# IWRL6432 register map
File version: 1.0
CPU: CM4 1.0, other endian, MPU, FPU, 3 interrupt priority bits
Registers are 32-bit, read-write, reset 0x0 unless marked. A register's access mark holds for its fields unless they carry their own. Offsets are from the block's base; [hi:lo] are bit positions.

## APP_PWM (part 2 of 2)
Base 0x57F7FC00
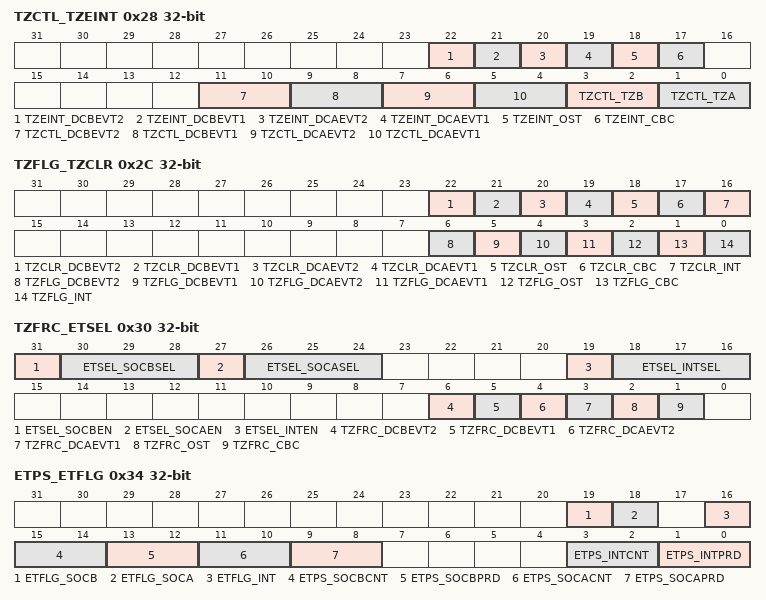
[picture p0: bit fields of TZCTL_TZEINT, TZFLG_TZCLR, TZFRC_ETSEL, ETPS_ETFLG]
0x28 TZCTL_TZEINT — Trip-Zone Control Register/ Trip-Zone Enable Interrupt Register
  [22] TZEINT_DCBEVT2 — [22:22] Digital Comparator Output B Event 2 Interrupt Enable 0 Disabled 1 Enabled
  [21] TZEINT_DCBEVT1 — [21:21] Digital Comparator Output B Event 1 Interrupt Enable 0 Disabled 1 Enabled
  [20] TZEINT_DCAEVT2 — [20:20] Digital Comparator Output A Event 2 Interrupt Enable 0 Disabled 1 Enabled
  [19] TZEINT_DCAEVT1 — [19:19] Digital Comparator Output A Event 1 Interrupt Enable 0 Disabled 1 Enabled
  [18] TZEINT_OST — [18:18] Trip-zone One-Shot Interrupt Enable 0 Disable one-shot interrupt generation 1 Enable Interrupt generation; a one-shot trip event will cause a EPWMx_TZINT VIM interrupt
  [17] TZEINT_CBC — [17:17] Trip-zone Cycle-by-Cycle Interrupt Enable 0 Disable cycle-by-cycle interrupt generation. 1 Enable interrupt generation; a cycle-by-cycle trip event will cause an EPWMx_TZINT VIM interrupt
  [11:10] TZCTL_DCBEVT2 — [11:10] Digital Compare Output B Event 2 Action On EPWMxB: 0 High-impedance (EPWMxB = High-impedance state) 1h Force EPWMxB to a high state. 2h Force EPWMxB to a low state. 3h Do Nothing, trip action is disabled
  [9:8] TZCTL_DCBEVT1 — [9:8] Digital Compare Output B Event 1 Action On EPWMxB: 0 High-impedance (EPWMxB = High-impedance state) 1h Force EPWMxB to a high state. 2h Force EPWMxB to a low state. 3h Do Nothing, trip action is disabled
  [7:6] TZCTL_DCAEVT2 — [7:6] Digital Compare Output A Event 2 Action On EPWMxA: 0 High-impedance (EPWMxA = High-impedance state) 1h Force EPWMxA to a high state. 2h Force EPWMxA to a low state. 3h Do Nothing, trip action is disabled
  [5:4] TZCTL_DCAEVT1 — [5:4] Digital Compare Output A Event 1 Action On EPWMxA: 0 High-impedance (EPWMxA = High-impedance state) 1h Force EPWMxA to a high state. 2h Force EPWMxA to a low state. 3h Do Nothing, trip action is disabled
  [3:2] TZCTL_TZB — [3:2] When a trip event occurs the following action is taken on output EPWMxB. Which trip-zone pins can cause an event is defined in the TZSEL register. 0 High-impedance (EPWMxB = High-impedance state) 1h Force EPWMxB to a high state 2h Force EPWMxB to a low state 3h Do nothing, no action is taken on EPWMxB.
  [1:0] TZCTL_TZA — [1:0] When a trip event occurs the following action is taken on output EPWMxA. Which trip-zone pins can cause an event is defined in the TZSEL register. 0 High-impedance (EPWMxA = High-impedance state) 1h Force EPWMxA to a high state 2h Force EPWMxA to a low state 3h Do nothing, no action is taken on EPWMxA
0x2C TZFLG_TZCLR — Trip-Zone Flag Register/ Trip-Zone Clear Register
  [22] TZCLR_DCBEVT2 — [22:22] Clear Flag for Digital Compare Output B Event 2 0 Writing 0 has no effect. This bit always reads back 0. 1 Writing 1 clears the DCBEVT2 event trip condition.
  [21] TZCLR_DCBEVT1 — [21:21] Clear Flag for Digital Compare Output B Event 1 0 Writing 0 has no effect. This bit always reads back 0. 1 Writing 1 clears the DCBEVT1 event trip condition
  [20] TZCLR_DCAEVT2 — [20:20] Clear Flag for Digital Compare Output A Event 2 0 Writing 0 has no effect. This bit always reads back 0. 1 Writing 1 clears the DCAEVT2 event trip condition
  [19] TZCLR_DCAEVT1 — [19:19] Clear Flag for Digital Compare Output A Event 1 0 Writing 0 has no effect. This bit always reads back 0. 1 Writing 1 clears the DCAEVT1 event trip condition.
  [18] TZCLR_OST — [18:18] Clear Flag for One-Shot Trip (OST) Latch 0 Has no effect. Always reads back a 0. 1 Clears this Trip (set) condition.
  [17] TZCLR_CBC — [17:17] Clear Flag for Cycle-By-Cycle (CBC) Trip Latch 0 Has no effect. Always reads back a 0. 1 Clears this Trip (set) condition.
  [16] TZCLR_INT — [16:16] Global Interrupt Clear Flag 0 Has no effect. Always reads back a 0. 1 Clears the trip-interrupt flag for this ePWM module (TZFLG[INT]). NOTE: No further EPWMx_TZINT VIM interrupts will be generated until the flag is cleared. If the TZFLG[INT] bit is cleared and any of the other flag bits are set, then another interrupt pulse will be generated. Clearing all flag bits will prevent further interrupts.
  [6] TZFLG_DCBEVT2 — [6:6] Latched Status Flag for Digital Compare Output B Event 2 0 Indicates no trip event has occurred on DCBEVT2 1 Indicates a trip event has occurred for the event defined for DCBEVT2
  [5] TZFLG_DCBEVT1 — [5:5] Latched Status Flag for Digital Compare Output B Event 1 0 Indicates no trip event has occurred on DCBEVT1 1 Indicates a trip event has occurred for the event defined for DCBEVT1
  [4] TZFLG_DCAEVT2 — [4:4] Latched Status Flag for Digital Compare Output A Event 2 0 Indicates no trip event has occurred on DCAEVT2 1 Indicates a trip event has occurred for the event defined for DCAEVT2
  [3] TZFLG_DCAEVT1 — [3:3] Latched Status Flag for Digital Compare Output A Event 1 0 Indicates no trip event has occurred on DCAEVT1 1 Indicates a trip event has occurred for the event defined for DCAEVT1
  [2] TZFLG_OST — [2:2] Latched Status Flag for A One-Shot Trip Event 0 No one-shot trip event has occurred. 1 Indicates a trip event has occurred on a pin selected as a one-shot trip source. This bit is cleared by writing the appropriate value to the TZCLR register
  [1] TZFLG_CBC — [1:1] Latched Status Flag for Cycle-By-Cycle Trip Event 0 No cycle-by-cycle trip event has occurred. 1 Indicates a trip event has occurred on a signal selected as a cycle-by-cycle trip source. The TZFLG[CBC] bit will remain set until it is manually cleared by the user. If the cycle-by-cycle trip event is still present when the CBC bit is cleared, then CBC will be immediately set again. The specified condition on the signal is automatically cleared when the ePWM time-base counter reaches zero (TBCTR = 0x0000) if the trip condition is no longer present. The condition on the signal is only cleared when the TBCTR = 0x0000 no matter where in the cycle the CBC flag is cleared. This bit is cleared by writing the appropriate value to the TZCLR register
  [0] TZFLG_INT — [0:0] Latched Trip Interrupt Status Flag 0 Indicates no interrupt has been generated. 1 Indicates an EPWMx_TZINT VIM interrupt was generated because of a trip condition. No further EPWMx_TZINT VIM interrupts will be generated until this flag is cleared. If the interrupt flag is cleared when either CBC or OST is set, then another interrupt pulse will be generated. Clearing all flag bits will prevent further interrupts. This bit is cleared by writing the appropriate value to the TZCLR register
0x30 TZFRC_ETSEL — Trip-Zone Force Register / Event-Trigger Selection Register
  [31] ETSEL_SOCBEN — [31:31] Enable the ADC Start of Conversion B (EPWMxSOCB) Pulse 0 Disable EPWMxSOCB. 1 Enable EPWMxSOCB pulse
  [30:28] ETSEL_SOCBSEL — [30:28] EPWMxSOCB Selection Options These bits determine when a EPWMxSOCB pulse will be generated. 0 Enable DCBEVT1.soc event 1h Enable event time-base counter equal to zero. (TBCTR = 0x0000) 2h Enable event time-base counter equal to period (TBCTR = TBPRD) 3h Enable event time-base counter equal to zero or period (TBCTR = 0x0000 or TBCTR = TBPRD). This mode is useful in up-down count mode. 4h Enable event time-base counter equal to CMPA when the timer is incrementing. 5h Enable event time-base counter equal to CMPA when the timer is decrementing. 6h Enable event: time-base counter equal to CMPB when the timer is incrementing. 7h Enable event: time-base counter equal to CMPB when the timer is decrementing
  [27] ETSEL_SOCAEN — [27:27] Enable the ADC Start of Conversion A (EPWMxSOCA) Pulse 0 Disable EPWMxSOCA. 1 Enable EPWMxSOCA pulse.
  [26:24] ETSEL_SOCASEL — [26:24] EPWMxSOCA Selection Options These bits determine when a EPWMxSOCA pulse will be generated. 0 Enable DCAEVT1.soc event 1h Enable event time-base counter equal to zero. (TBCTR = 0x0000) 2h Enable event time-base counter equal to period (TBCTR = TBPRD) 3h Enable event time-base counter equal to zero or period (TBCTR = 0x0000 or TBCTR = TBPRD). This mode is useful in up-down count mode. 4h Enable event time-base counter equal to CMPA when the timer is incrementing. 5h Enable event time-base counter equal to CMPA when the timer is decrementing. 6h Enable event: time-base counter equal to CMPB when the timer is incrementing. 7h Enable event: time-base counter equal to CMPB when the timer is decrementing
  [19] ETSEL_INTEN — [19:19] Enable ePWM Interrupt (EPWMx_INT) Generation 0 Disable EPWMx_INT generation 1 Enable EPWMx_INT generation
  [18:16] ETSEL_INTSEL — [18:16] ePWM Interrupt (EPWMx_INT) Selection Options 0 Reserved 1h Enable event time-base counter equal to zero. (TBCTR = 0x0000) 2h Enable event time-base counter equal to period (TBCTR = TBPRD) 3h Enable event time-base counter equal to zero or period (TBCTR = 0x0000 or TBCTR = TBPRD). This mode is useful in up-down count mode. 4h Enable event time-base counter equal to CMPA when the timer is incrementing. 5h Enable event time-base counter equal to CMPA when the timer is decrementing. 6h Enable event: time-base counter equal to CMPB when the timer is incrementing. 7h Enable event: time-base counter equal to CMPB when the timer is decrementing.
  [6] TZFRC_DCBEVT2 — [6:6] Force Flag for Digital Compare Output B Event 2 0 Writing 0 has no effect. This bit always reads back 0. 1 Writing 1 forces the DCBEVT2 event trip condition and sets the TZFLG[DCBEVT2] bit.
  [5] TZFRC_DCBEVT1 — [5:5] Force Flag for Digital Compare Output B Event 1 0 Writing 0 has no effect. This bit always reads back 0. 1 Writing 1 forces the DCBEVT1 event trip condition and sets the TZFLG[DCBEVT1] bit
  [4] TZFRC_DCAEVT2 — [4:4] Force Flag for Digital Compare Output A Event 2 0 Writing 0 has no effect. This bit always reads back 0. 1 Writing 1 forces the DCAEVT2 event trip condition and sets the TZFLG[DCAEVT2] bit
  [3] TZFRC_DCAEVT1 — [3:3] Force Flag for Digital Compare Output A Event 1 0 Writing 0 has no effect. This bit always reads back 0 1 Writing 1 forces the DCAEVT1 event trip condition and sets the TZFLG[DCAEVT1] bit
  [2] TZFRC_OST — [2:2] Force a One-Shot Trip Event via Software 0 Writing of 0 is ignored. Always reads back a 0. 1 Forces a one-shot trip event and sets the TZFLG[OST] bit
  [1] TZFRC_CBC — [1:1] Force a Cycle-by-Cycle Trip Event via Software 0 Writing of 0 is ignored. Always reads back a 0. 1 Forces a cycle-by-cycle trip event and sets the TZFLG[CBC] bit.
0x34 ETPS_ETFLG — Event-Trigger Pre-Scale Register/ Event-Trigger Flag Register
  [19] ETFLG_SOCB — [19:19] Latched ePWM ADC Start-of-Conversion B (EPWMxSOCB) Status Flag 0 Indicates no EPWMxSOCB event occurred 1 Indicates that a start of conversion pulse was generated on EPWMxSOCB. The EPWMxSOCB output will continue to be generated even if the flag bit is set.
  [18] ETFLG_SOCA — [18:18] Latched ePWM ADC Start-of-Conversion A (EPWMxSOCA) Status Flag Unlike the ETFLG[INT] flag, the EPWMxSOCA output will continue to pulse even if the flag bit is set. 0 Indicates no event occurred 1 Indicates that a start of conversion pulse was generated on EPWMxSOCA. The EPWMxSOCA output will continue to be generated even if the flag bit is set
  [16] ETFLG_INT — [16:16] Latched ePWM Interrupt (EPWMx_INT) Status Flag 0 Indicates no event occurred 1 Indicates that an ePWMx interrupt (EWPMx_INT) was generated. No further interrupts will be generated until the flag bit is cleared. Up to one interrupt can be pending while the ETFLG[INT] bit is still set. If an interrupt is pending, it will not be generated until after the ETFLG[INT] bit is cleared
  [15:14] ETPS_SOCBCNT — [15:14] ePWM ADC Start-of-Conversion B Event (EPWMxSOCB) Counter Register These bits indicate how many selected ETSEL[SOCBSEL] events have occurred: 0 No events have occurred. 1h 1 event has occurred. 2h 2 events have occurred. 3h 3 events have occurred
  [13:12] ETPS_SOCBPRD — [13:12] ePWM ADC Start-of-Conversion B Event (EPWMxSOCB) Period Select These bits determine how many selected ETSEL[SOCBSEL] events need to occur before an EPWMxSOCB pulse is generated. To be generated, the pulse must be enabled (ETSEL[SOCBEN] = 1). The SOCB pulse will be generated even if the status flag is set from a previous start of conversion (ETFLG[SOCB] = 1). Once the SOCB pulse is generated, the ETPS[SOCBCNT] bits will automatically be cleared. 0 Disable the SOCB event counter. No EPWMxSOCB pulse will be generated 1h Generate the EPWMxSOCB pulse on the first event: ETPS[SOCBCNT] = 0,1 2h Generate the EPWMxSOCB pulse on the second event: ETPS[SOCBCNT] = 1,0 3h Generate the EPWMxSOCB pulse on the third event: ETPS[SOCBCNT] = 1,1
  [11:10] ETPS_SOCACNT — [11:10] ePWM ADC Start-of-Conversion A Event (EPWMxSOCA) Counter Register These bits indicate how many selected ETSEL[SOCASEL] events have occurred: 0 No events have occurred. 1h 1 event has occurred. 2h 2 events have occurred. 3h 3 events have occurred.
  [9:8] ETPS_SOCAPRD — [9:8] ePWM ADC Start-of-Conversion A Event (EPWMxSOCA) Period Select These bits determine how many selected ETSEL[SOCASEL] events need to occur before an EPWMxSOCA pulse is generated. To be generated, the pulse must be enabled (ETSEL[SOCAEN] = 1). The SOCA pulse will be generated even if the status flag is set from a previous start of conversion (ETFLG[SOCA] = 1). Once the SOCA pulse is generated, the ETPS[SOCACNT] bits will automatically be cleared. 0 Disable the SOCA event counter. No EPWMxSOCA pulse will be generated 1h Generate the EPWMxSOCA pulse on the first event: ETPS[SOCACNT] = 0,1 2h Generate the EPWMxSOCA pulse on the second event: ETPS[SOCACNT] = 1,0 3h Generate the EPWMxSOCA pulse on the third event: ETPS[SOCACNT] = 1,1
  [3:2] ETPS_INTCNT — [3:2] ePWM Interrupt Event (EPWMx_INT) Counter Register These bits indicate how many selected ETSEL[INTSEL] events have occurred. These bits are automatically cleared when an interrupt pulse is generated. If interrupts are disabled, ETSEL[INT] = 0 or the interrupt flag is set, ETFLG[INT] = 1, the counter will stop counting events when it reaches the period value ETPS[INTCNT] = ETPS[INTPRD]. 0 No events have occurred. 1h 1 event has occurred. 2h 2 events have occurred. 3h 3 events have occurred.
  [1:0] ETPS_INTPRD — [1:0] ePWM Interrupt (EPWMx_INT) Period Select These bits determine how many selected ETSEL[INTSEL] events need to occur before an interrupt is generated. To be generated, the interrupt must be enabled (ETSEL[INT] = 1). If the interrupt status flag is set from a previous interrupt (ETFLG[INT] = 1) then no interrupt will be generated until the flag is cleared via the ETCLR[INT] bit. This allows for one interrupt to be pending while another is still being serviced. Once the interrupt is generated, the ETPS[INTCNT] bits will automatically be cleared. Writing a INTPRD value that is the same as the current counter value will trigger an interrupt if it is enabled and the status flag is clear. Writing a INTPRD value that is less than the current counter value will result in an undefined state. If a counter event occurs at the same instant as a new zero or non-zero INTPRD value is written, the counter is incremented. 0 Disable the interrupt event counter. No interrupt will be generated and ETFRC[INT] is ignored. 1h Generate an interrupt on the first event INTCNT = 01 (first event) 2h Generate interrupt on ETPS[INTCNT] = 1,0 (second event) 3h Generate interrupt on ETPS[INTCNT] = 1,1 (third event)
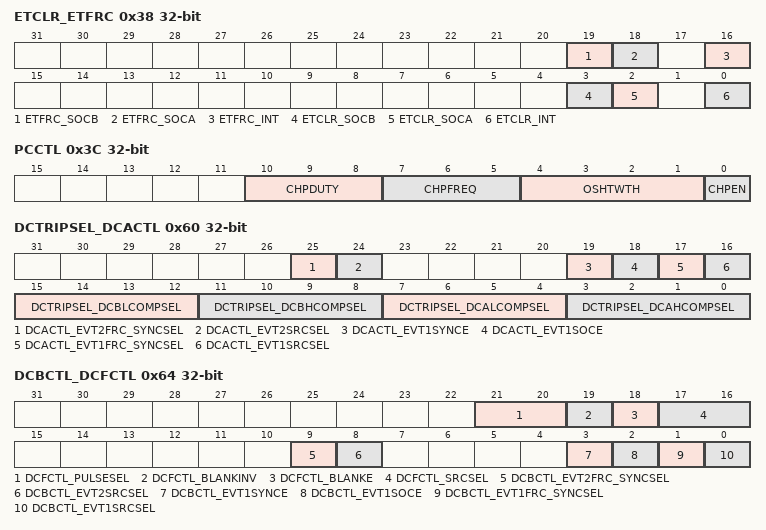
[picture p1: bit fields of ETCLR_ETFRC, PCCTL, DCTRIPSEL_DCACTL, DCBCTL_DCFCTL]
0x38 ETCLR_ETFRC — Event-Trigger Clear Register/ Event-Trigger Force Register
  [19] ETFRC_SOCB — [19:19] SOCB Force Bit. The SOCB pulse will only be generated if the event is enabled in the ETSEL register. The ETFLG[SOCB] flag bit will be set regardless. 0 Has no effect. Always reads back a 0. 1 Generates a pulse on EPWMxSOCB and sets the SOCBFLG bit. This bit is used for test purposes
  [18] ETFRC_SOCA — [18:18] SOCA Force Bit. The SOCA pulse will only be generated if the event is enabled in the ETSEL register. The ETFLG[SOCA] flag bit will be set regardless. 0 Writing 0 to this bit will be ignored. Always reads back a 0. 1 Generates a pulse on EPWMxSOCA and set the SOCAFLG bit. This bit is used for test purposes
  [16] ETFRC_INT — [16:16] INT Force Bit. The interrupt will only be generated if the event is enabled in the ETSEL register. The INT flag bit will be set regardless. 0 Writing 0 to this bit will be ignored. Always reads back a 0. 1 Generates an interrupt on EPWMxINT and set the INT flag bit. This bit is used for test purposes
  [3] ETCLR_SOCB — [3:3] ePWM ADC Start-of-Conversion B (EPWMxSOCB) Flag Clear Bit 0 Writing a 0 has no effect. Always reads back a 0 1 Clears the ETFLG[SOCB] flag bit
  [2] ETCLR_SOCA — [2:2] ePWM ADC Start-of-Conversion A (EPWMxSOCA) Flag Clear Bit 0 Writing a 0 has no effect. Always reads back a 0 1 Clears the ETFLG[SOCA] flag bit
  [0] ETCLR_INT — [0:0] ePWM Interrupt (EPWMx_INT) Flag Clear Bit 0 Writing a 0 has no effect. Always reads back a 0 1 Clears the ETFLG[INT] flag bit and enable further interrupts pulses to be generated
0x3C PCCTL — PWM-Chopper Control Register
  [10:8] CHPDUTY — [10:8] Chopping Clock Duty Cycle 0 Duty = 1/8 (12.5%) 1h Duty = 2/8 (25.0%) 2h Duty = 3/8 (37.5%) 3h Duty = 4/8 (50.0%) 4h Duty = 5/8 (62.5%) 5h Duty = 6/8 (75.0%) 6h Duty = 7/8 (87.5%) 7h Reserved
  [7:5] CHPFREQ — [7:5] Chopping Clock Frequency 0 Divide by 1 (no prescale, = 12.5 MHz at 100 MHz VCLK3) 1h Divide by 2 (6.25 MHz at 100 MHz VCLK3) 2h Divide by 3 (4.16 MHz at 100 MHz VCLK3) 3h Divide by 4 (3.12 MHz at 100 MHz VCLK3) 4h Divide by 5 (2.50 MHz at 100 MHz VCLK3) 5h Divide by 6 (2.08 MHz at 100 MHz VCLK3) 6h Divide by 7 (1.78 MHz at 100 MHz VCLK3) 7h Divide by 8 (1.56 MHz at 100 MHz VCLK3)
  [4:1] OSHTWTH — [4:1] One-Shot Pulse Width 0 1 x VCLK3 / 8 wide ( = 80 nS at 100 MHz VCLK3) 1h 2 x VCLK3 / 8 wide ( = 160 nS at 100 MHz VCLK3) 2h 3 x VCLK3 / 8 wide ( = 240 nS at 100 MHz VCLK3) 3h 4 x VCLK3 / 8 wide ( = 320 nS at 100 MHz VCLK3) 4h 5 x VCLK3 / 8 wide ( = 400 nS at 100 MHz VCLK3) 5h 6 x VCLK3 / 8 wide ( = 480 nS at 100 MHz VCLK3) 6h 7 x VCLK3 / 8 wide ( = 560 nS at 100 MHz VCLK3) 7h 8 x VCLK3 / 8 wide ( = 640 nS at 100 MHz VCLK3) 8h 9 x VCLK3 / 8 wide ( = 720 nS at 100 MHz VCLK3) 9h 10 x VCLK3 / 8 wide ( = 800 nS at 100 MHz VCLK3) Ah 11 x VCLK3 / 8 wide ( = 880 nS at 100 MHz VCLK3) Bh 12 x VCLK3 / 8 wide ( = 960 nS at 100 MHz VCLK3) Ch 13 x VCLK3 / 8 wide ( = 1040 nS at 100 MHz VCLK3) Dh 14 x VCLK3 / 8 wide ( = 1120 nS at 100 MHz VCLK3) Eh 15 x VCLK3 / 8 wide ( = 1200 nS at 100 MHz VCLK3) Fh 16 x VCLK3 / 8 wide ( = 1280 nS at 100 MHz VCLK3)
  [0] CHPEN — [0:0] PWM-chopping Enable 0 Disable (bypass) PWM chopping function 1 Enable chopping function
0x60 DCTRIPSEL_DCACTL — Digital Compare Trip Select Register/ Digital Compare A Control Register
  [25] DCACTL_EVT2FRC_SYNCSEL — [25:25] DCAEVT2 Force Synchronization Signal Select 0 Source Is Synchronous Signal 1 Source Is Asynchronous Signal
  [24] DCACTL_EVT2SRCSEL — [24:24] DCAEVT2 Source Signal Select 0 Source Is DCAEVT2 Signal 1 Source Is DCEVTFILT Signal
  [19] DCACTL_EVT1SYNCE — [19:19] DCAEVT1 SYNC, Enable/Disable 0 SYNC Generation Disabled 1 SYNC Generation Enabled
  [18] DCACTL_EVT1SOCE — [18:18] DCAEVT1 SOC, Enable/Disable 0 SOC Generation Disabled 1 SOC Generation Enabled
  [17] DCACTL_EVT1FRC_SYNCSEL — [17:17] DCAEVT1 Force Synchronization Signal Select 0 Source Is Synchronous Signal 1 Source Is Asynchronous Signal
  [16] DCACTL_EVT1SRCSEL — [16:16] DCAEVT1 Source Signal Select 0 Source Is DCAEVT1 Signal 1 Source Is DCEVTFILT Signal
  [15:12] DCTRIPSEL_DCBLCOMPSEL — [15:12] Digital Compare B Low Input Select Defines the source for the DCBL input. The TZ signals, when used as trip signals, are treated as normal inputs and can be defined as active high or active low. 0 TZ1 input 1h TZ2 input 2h TZ3 input All other values Values not shown are reserved. If a device does not have a particular comparitor, then that option is reserved.
  [11:8] DCTRIPSEL_DCBHCOMPSEL — [11:8] Digital Compare B High Input Select Defines the source for the DCBH input. The TZ signals, when used as trip signals, are treated as normal inputs and can be defined as active high or active low. 0 TZ1 input 1h TZ2 input 2h TZ3 input All other values Values not shown are reserved. If a device does not have a particular comparitor, then that option is reserved.
  [7:4] DCTRIPSEL_DCALCOMPSEL — [7:4] Digital Compare A Low Input Select Defines the source for the DCAL input. The TZ signals, when used as trip signals, are treated as normal inputs and can be defined as active high or active low. 0 TZ1 input 1h TZ2 input 2h TZ3 input All other values Values not shown are reserved. If a device does not have a particular comparitor, then that option is reserved.
  [3:0] DCTRIPSEL_DCAHCOMPSEL — [3:0] Digital Compare A High Input Select Defines the source for the DCAH input. The TZ signals, when used as trip signals, are treated as normal inputs and can be defined as active high or active low. 0 TZ1 input 1h TZ2 input 2h TZ3 input All other values Values not shown are reserved. If a device does not have a particular comparitor, then that option is reserved.
0x64 DCBCTL_DCFCTL — Digital Compare B Control Register/ Digital Compare Filter Control Register
  [21:20] DCFCTL_PULSESEL — [21:20] Pulse Select For Blanking & Capture Alignment 0 Time-base counter equal to period (TBCTR = TBPRD) 1h Time-base counter equal to zero (TBCTR = 0x0000) 2h-3h Reserved
  [19] DCFCTL_BLANKINV — [19:19] Blanking Window Inversion 0 Blanking window not inverted 1 Blanking window inverted
  [18] DCFCTL_BLANKE — [18:18] Blanking Window Enable/Disable 0 Blanking window is disabled 1 Blanking window is enabled
  [17:16] DCFCTL_SRCSEL — [17:16] Filter Block Signal Source Select 0 Source Is DCAEVT1 Signal 1h Source Is DCAEVT2 Signal 2h Source Is DCBEVT1 Signal 3h Source Is DCBEVT2 Signal
  [9] DCBCTL_EVT2FRC_SYNCSEL — [9:9] DCBEVT2 Force Synchronization Signal Select 0 Source Is Synchronous Signal 1 Source Is Asynchronous Signal
  [8] DCBCTL_EVT2SRCSEL — [8:8] DCBEVT2 Source Signal Select 0 Source Is DCBEVT2 Signal 1 Source Is DCEVTFILT Signal
  [3] DCBCTL_EVT1SYNCE — [3:3] DCBEVT1 SYNC, Enable/Disable 0 SYNC Generation Disabled 1 SYNC Generation Enabled
  [2] DCBCTL_EVT1SOCE — [2:2] DCBEVT1 SOC, Enable/Disable 0 SOC Generation Disabled 1 SOC Generation Enabled
  [1] DCBCTL_EVT1FRC_SYNCSEL — [1:1] DCBEVT1 Force Synchronization Signal Select 0 Source Is Synchronous Signal 1 Source Is Asynchronous Signal
  [0] DCBCTL_EVT1SRCSEL — [0:0] DCBEVT1 Source Signal Select 0 Source Is DCBEVT1 Signal 1 Source Is DCEVTFILT Signal
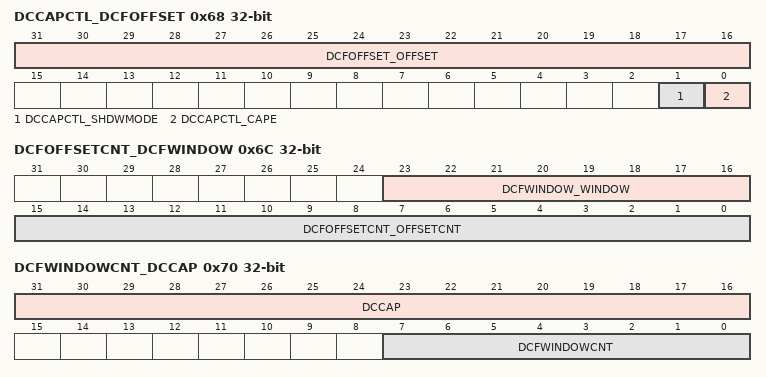
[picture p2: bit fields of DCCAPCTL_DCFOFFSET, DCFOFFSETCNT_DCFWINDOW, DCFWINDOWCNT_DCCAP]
0x68 DCCAPCTL_DCFOFFSET — Digital Compare Capture Control Register/ Digital Compare Filter Offset Register
  [31:16] DCFOFFSET_OFFSET — [31:16] Blanking Window Offset These 16-bits specify the number of TBCLK cycles from the blanking window reference to the point when the blanking window is applied. The blanking window reference is either period or zero as defined by the DCFCTL[PULSESEL] bit. This offset register is shadowed and the active register is loaded at the reference point defined by DCFCTL[PULSESEL]. The offset counter is also initialized and begins to count down when the active register is loaded. When the counter expires, the blanking window is applied. If the blanking window is currently active, then the blanking window counter is restarted.
  [1] DCCAPCTL_SHDWMODE — [1:1] TBCTR Counter Capture Shadow Select Mode 0 Enable shadow mode. The DCCAP active register is copied to shadow register on a TBCTR = TBPRD or TBCTR = zero event as defined by the DCFCTL[PULSESEL] bit. CPU reads of the DCCAP register will return the shadow register contents. 1 Active Mode. In this mode the shadow register is disabled. CPU reads from the DCCAP register will always return the active register contents
  [0] DCCAPCTL_CAPE — [0:0] TBCTR Counter Capture Enable/Disable 0 Disable the time-base counter capture. 1 Enable the time-base counter capture.
0x6C DCFOFFSETCNT_DCFWINDOW — Digital Compare Filter Offset Counter Register/ Digital Compare Filter Window Register
  [23:16] DCFWINDOW_WINDOW — [23:16] Blanking Window Width 0 No blanking window is generated. 1h-FFh Specifies the width of the blanking window in TBCLK cycles. The blanking window begins when the offset counter expires. When this occurs, the window counter is loaded and begins to count down. If the blanking window is currently active and the offset counter expires, the blanking window counter is restarted. The blanking window can cross a PWM period boundary.
  [15:0] DCFOFFSETCNT_OFFSETCNT — [15:0] Blanking Offset Counter These 16-bits are read only and indicate the current value of the offset counter. The counter counts down to zero and then stops until it is re-loaded on the next period or zero event as defined by the DCFCTL[PULSESEL] bit. The offset counter is not affected by the free/soft emulation bits. That is, it will always continue to count down if the device is halted by a emulation stop.
0x70 DCFWINDOWCNT_DCCAP — Digital Compare Filter Window Counter Register/ Digital Compare Counter Capture Register
  [31:16] DCCAP — [31:16] Digital Compare Time-Base Counter Capture To enable time-base counter capture, set the DCCAPCLT[CAPE] bit to 1. If enabled, reflects the value of the time-base counter (TBCTR) on the low to high edge transition of a filtered (DCEVTFLT) event. Further capture events are ignored until the next period or zero as selected by the DCFCTL[PULSESEL] bit. Shadowing of DCCAP is enabled and disabled by the DCCAPCTL[SHDWMODE] bit. By default this register is shadowed. ΓÇó If DCCAPCTL[SHDWMODE] = 0, then the shadow is enabled. In this mode, the active register is copied to the shadow register on the TBCTR = TBPRD or TBCTR = zero as defined by the DCFCTL[PULSESEL] bit. CPU reads of this register will return the shadow register value. ΓÇó If DCCAPCTL[SHDWMODE] = 1, then the shadow register is disabled. In this mode, CPU reads will return the active register value. The active and shadow registers share the same memory map address.
  [7:0] DCFWINDOWCNT — [7:0] 0-FFh Blanking Window Counter These 8 bits are read only and indicate the current value of the window counter. The counter counts down to zero and then stops until it is re-loaded when the offset counter reaches zero again.
